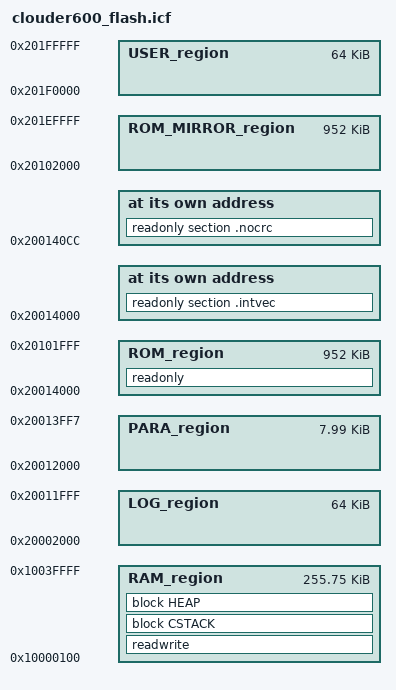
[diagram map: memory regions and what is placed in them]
/*###ICF### Section handled by ICF editor, don't touch! ****/
/*-Editor annotation file-*/
/* IcfEditorFile="$TOOLKIT_DIR$\config\ide\IcfEditor\cortex_v1_0.xml" */
/*-Specials-*/
define symbol __ICFEDIT_intvec_start__ = 0x20014000;

/*-Memory Regions-*/
define symbol __ICFEDIT_region_RAM_size__  = 0x3FEFF;
define symbol __ICFEDIT_region_RAM_start__ = 0x10000100;
define symbol __ICFEDIT_region_RAM_end__   = 0x1003FFFF;

define symbol __ICFEDIT_region_BL_size__  = 0x2000;
define symbol __ICFEDIT_region_BL_start__ = 0x20000000;
define symbol __ICFEDIT_region_BL_end__   = 0x20001fff;

define symbol __ICFEDIT_region_LOG_size__  = 0x10000;
define symbol __ICFEDIT_region_LOG_start__ = 0x20002000;
define symbol __ICFEDIT_region_LOG_end__   = 0x20011fff;

define symbol __ICFEDIT_region_PARA_ROM_CRC__ = 0x200140cc;

define symbol __ICFEDIT_region_PARA_size__  = 0x2000;
define symbol __ICFEDIT_region_PARA_start__ = 0x20012000;
define symbol __ICFEDIT_region_PARA_end__   = 0x20013ff7;

define symbol __ICFEDIT_region_ROM_size__  = 0xEE000;
define symbol __ICFEDIT_region_ROM_start__ = 0x20014000;
define symbol __ICFEDIT_region_ROM_end__   = 0x20101FFF;

define symbol __ICFEDIT_region_ROM_MIRROR_size__  = 0xEE000;
define symbol __ICFEDIT_region_ROM_MIRROR_start__ = 0x20102000;
define symbol __ICFEDIT_region_ROM_MIRROR_end__   = 0x201EFFFF;

define symbol __ICFEDIT_region_USER_size__  = 0x10000;
define symbol __ICFEDIT_region_USER_start__ = 0x201F0000;
define symbol __ICFEDIT_region_USER_end__   = 0x201FFFFF;
/*-Sizes-*/

define symbol __ICFEDIT_size_cstack__ = 0x3200;
define symbol __ICFEDIT_size_heap__   = 0x1C000;

/**** End of ICF editor section. ###ICF###*/

define memory mem with size = 4G;
define region RAM_region   = mem:[from __ICFEDIT_region_RAM_start__   to __ICFEDIT_region_RAM_end__];

define region LOG_region   = mem:[from __ICFEDIT_region_LOG_start__   to __ICFEDIT_region_LOG_end__];
define region PARA_region   = mem:[from __ICFEDIT_region_PARA_start__   to __ICFEDIT_region_PARA_end__];
define region ROM_region   = mem:[from __ICFEDIT_region_ROM_start__   to __ICFEDIT_region_ROM_end__];
define region ROM_MIRROR_region   = mem:[from __ICFEDIT_region_ROM_MIRROR_start__   to __ICFEDIT_region_ROM_MIRROR_end__];
define region USER_region   = mem:[from __ICFEDIT_region_USER_start__   to __ICFEDIT_region_USER_end__];

define block CSTACK    with alignment = 8, size = __ICFEDIT_size_cstack__   { };
define block HEAP      with alignment = 8, size = __ICFEDIT_size_heap__     { };

initialize by copy { readwrite };
do not initialize  { section .noinit };


place at address mem:__ICFEDIT_intvec_start__ { readonly section .intvec };
place at address mem:__ICFEDIT_region_PARA_ROM_CRC__ { readonly section .nocrc };

place in ROM_region   { readonly };
place in RAM_region   { readwrite,
                        block CSTACK, block HEAP };

export symbol __ICFEDIT_size_cstack__;
export symbol __ICFEDIT_size_heap__;
export symbol __ICFEDIT_intvec_start__;

export symbol __ICFEDIT_region_RAM_size__;
export symbol __ICFEDIT_region_RAM_start__;
export symbol __ICFEDIT_region_RAM_end__;

export symbol __ICFEDIT_region_BL_size__;
export symbol __ICFEDIT_region_BL_start__;
export symbol __ICFEDIT_region_BL_end__;

export symbol __ICFEDIT_region_LOG_size__;
export symbol __ICFEDIT_region_LOG_start__;
export symbol __ICFEDIT_region_LOG_end__;

export symbol __ICFEDIT_region_PARA_size__;
export symbol __ICFEDIT_region_PARA_start__;
export symbol __ICFEDIT_region_PARA_end__;

export symbol __ICFEDIT_region_ROM_size__;
export symbol __ICFEDIT_region_ROM_start__;
export symbol __ICFEDIT_region_ROM_end__;

export symbol __ICFEDIT_region_ROM_MIRROR_size__;
export symbol __ICFEDIT_region_ROM_MIRROR_start__;
export symbol __ICFEDIT_region_ROM_MIRROR_end__;

export symbol __ICFEDIT_region_USER_size__;
export symbol __ICFEDIT_region_USER_start__;
export symbol __ICFEDIT_region_USER_end__;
